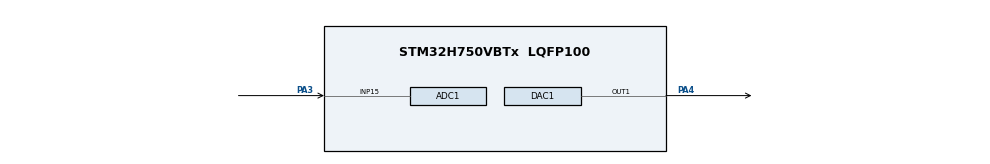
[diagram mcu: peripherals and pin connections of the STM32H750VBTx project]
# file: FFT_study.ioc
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ADC1.Channel-0\#ChannelRegularConversion=ADC_CHANNEL_15
ADC1.ClockPrescaler=ADC_CLOCK_ASYNC_DIV2
ADC1.ContinuousConvMode=DISABLE
ADC1.ConversionDataManagement=ADC_CONVERSIONDATA_DMA_CIRCULAR
ADC1.ExternalTrigConv=ADC_EXTERNALTRIG_T2_TRGO
ADC1.NbrOfConversionFlag=1
ADC1.OffsetNumber-0\#ChannelRegularConversion=ADC_OFFSET_NONE
ADC1.OffsetSignedSaturation-0\#ChannelRegularConversion=DISABLE
ADC1.Rank-0\#ChannelRegularConversion=1
ADC1.Resolution=ADC_RESOLUTION_12B
ADC1.SamplingTime-0\#ChannelRegularConversion=ADC_SAMPLETIME_64CYCLES_5
ADC1.master=1
CORTEX_M7.default_mode_Activation=1
DAC1.DAC_Channel-DAC_OUT1_ExtAndInt=DAC_CHANNEL_1
DAC1.DAC_Trigger-DAC_OUT1_ExtAndInt=DAC_TRIGGER_T2_TRGO
Dma.ADC1.1.Direction=DMA_PERIPH_TO_MEMORY
Dma.ADC1.1.EventEnable=DISABLE
Dma.ADC1.1.FIFOMode=DMA_FIFOMODE_DISABLE
Dma.ADC1.1.Instance=DMA2_Stream0
Dma.ADC1.1.MemDataAlignment=DMA_MDATAALIGN_HALFWORD
Dma.ADC1.1.MemInc=DMA_MINC_ENABLE
Dma.ADC1.1.Mode=DMA_CIRCULAR
Dma.ADC1.1.PeriphDataAlignment=DMA_PDATAALIGN_HALFWORD
Dma.ADC1.1.PeriphInc=DMA_PINC_DISABLE
Dma.ADC1.1.Polarity=HAL_DMAMUX_REQ_GEN_RISING
Dma.ADC1.1.Priority=DMA_PRIORITY_LOW
Dma.ADC1.1.RequestNumber=1
Dma.ADC1.1.SignalID=NONE
Dma.ADC1.1.SyncEnable=DISABLE
Dma.ADC1.1.SyncPolarity=HAL_DMAMUX_SYNC_NO_EVENT
Dma.ADC1.1.SyncRequestNumber=1
Dma.ADC1.1.SyncSignalID=NONE
Dma.DAC1_CH1.0.Direction=DMA_MEMORY_TO_PERIPH
Dma.DAC1_CH1.0.EventEnable=DISABLE
Dma.DAC1_CH1.0.FIFOMode=DMA_FIFOMODE_DISABLE
Dma.DAC1_CH1.0.Instance=DMA1_Stream0
Dma.DAC1_CH1.0.MemDataAlignment=DMA_MDATAALIGN_HALFWORD
Dma.DAC1_CH1.0.MemInc=DMA_MINC_ENABLE
Dma.DAC1_CH1.0.Mode=DMA_CIRCULAR
Dma.DAC1_CH1.0.PeriphDataAlignment=DMA_PDATAALIGN_HALFWORD
Dma.DAC1_CH1.0.PeriphInc=DMA_PINC_DISABLE
Dma.DAC1_CH1.0.Polarity=HAL_DMAMUX_REQ_GEN_RISING
Dma.DAC1_CH1.0.Priority=DMA_PRIORITY_LOW
Dma.DAC1_CH1.0.RequestNumber=1
Dma.DAC1_CH1.0.SignalID=NONE
Dma.DAC1_CH1.0.SyncEnable=DISABLE
Dma.DAC1_CH1.0.SyncPolarity=HAL_DMAMUX_SYNC_NO_EVENT
Dma.DAC1_CH1.0.SyncRequestNumber=1
Dma.DAC1_CH1.0.SyncSignalID=NONE
Dma.Request0=DAC1_CH1
Dma.Request1=ADC1
Mcu.Family=STM32H7
Mcu.Name=STM32H750VBTx
Mcu.Package=LQFP100
NVIC.DMA1_Stream0_IRQn=true\:0\:0\:false\:false\:true\:false\:true\:true
NVIC.DMA2_Stream0_IRQn=true\:0\:0\:false\:false\:true\:false\:true\:true
NVIC.PriorityGroup=NVIC_PRIORITYGROUP_4
PA3.Signal=ADCx_INP15
PA4.Signal=COMP_DAC11_group
ProjectManager.HeapSize=0x200
ProjectManager.StackSize=0x400
ProjectManager.TargetToolchain=MDK-ARM V5.32
RCC.ADCFreq_Value=80000000
RCC.APB1Freq_Value=120000000
RCC.APB2Freq_Value=120000000
RCC.APB3Freq_Value=120000000
RCC.APB4Freq_Value=120000000
RCC.CortexFreq_Value=480000000
RCC.D1PPRE=RCC_APB3_DIV2
RCC.D2PPRE1=RCC_APB1_DIV2
RCC.D2PPRE2=RCC_APB2_DIV2
RCC.D3PPRE=RCC_APB4_DIV2
RCC.DIVM1=4
RCC.DIVM2=4
RCC.DIVN1=60
RCC.DIVN2=10
RCC.HCLKFreq_Value=240000000
RCC.HPRE=RCC_HCLK_DIV2
RCC.PLL2FRACN=0
RCC.PLL2_VCI_Range=RCC_PLL2VCIRANGE_3
RCC.PLL3FRACN=0
RCC.PLLFRACN=0
RCC.SYSCLKFreq_VALUE=480000000
RCC.SYSCLKSource=RCC_SYSCLKSOURCE_PLLCLK
RCC.USBFreq_Value=480000000
SH.ADCx_INP15.0=ADC1_INP15,IN15-Single-Ended
SH.COMP_DAC11_group.0=DAC1_OUT1,DAC_OUT1_ExtAndInt
TIM2.AutoReloadPreload=TIM_AUTORELOAD_PRELOAD_ENABLE
TIM2.CounterMode=TIM_COUNTERMODE_UP
TIM2.Period=1874
TIM2.TIM_MasterOutputTrigger=TIM_TRGO_UPDATE
TIM3.Period=1874
TIM3.TIM_MasterOutputTrigger=TIM_TRGO_UPDATE
VP_MEMORYMAP_VS_MEMORYMAP.Mode=CurAppReg
VP_TIM2_VS_ClockSourceINT.Mode=Internal
VP_TIM3_VS_ClockSourceINT.Mode=Internal
board=custom

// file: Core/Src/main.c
/* USER CODE BEGIN Header */
/**
  ******************************************************************************
  * @file           : main.c
  * @brief          : Main program body
  ******************************************************************************
  * @attention
  *
  * Copyright (c) 2026 STMicroelectronics.
  * All rights reserved.
  *
  * This software is licensed under terms that can be found in the LICENSE file
  * in the root directory of this software component.
  * If no LICENSE file comes with this software, it is provided AS-IS.
  *
  ******************************************************************************
  */
/* USER CODE END Header */
#include "main.h"

/* USER CODE BEGIN Includes */
#include "arm_math.h"
/* USER CODE END Includes */

/* USER CODE BEGIN PD */
#define DMA_BUF __attribute__((section(".RAM_D1"), aligned(32)))

/* USER CODE END PD */

ADC_HandleTypeDef hadc1;
DMA_HandleTypeDef hdma_adc1;

DAC_HandleTypeDef hdac1;
DMA_HandleTypeDef hdma_dac1_ch1;

TIM_HandleTypeDef htim2;
TIM_HandleTypeDef htim3;

void SystemClock_Config(void);
static void MPU_Config(void);
static void MX_GPIO_Init(void);
static void MX_DMA_Init(void);
static void MX_DAC1_Init(void);
static void MX_ADC1_Init(void);
static void MX_TIM2_Init(void);
static void MX_TIM3_Init(void);

/* USER CODE BEGIN 0 */
uint16_t task=2;

DMA_BUF uint16_t dac_buf[128];

float32_t fft_input[256];
float32_t fft_out[256];
DMA_BUF uint16_t wave_sine[128]={0};
DMA_BUF uint16_t adc_buf[128];
volatile uint16_t adc_max=0, adc_min=4095;
volatile uint32_t adc_mean=0, adc_cross=0;
volatile uint8_t done=0;
/* USER CODE END 0 */

int main(void)
{

  /* MPU Configuration--------------------------------------------------------*/
  MPU_Config();

  /* MCU Configuration--------------------------------------------------------*/

  /* Reset of all peripherals, Initializes the Flash interface and the Systick. */
  HAL_Init();

  /* Configure the system clock */
  SystemClock_Config();

  /* Initialize all configured peripherals */
  MX_GPIO_Init();
  MX_DMA_Init();
  MX_DAC1_Init();
  MX_ADC1_Init();
  MX_TIM2_Init();
  MX_TIM3_Init();
  /* USER CODE BEGIN 2 */

  //开DAC，填波形表
  HAL_DAC_Start(&hdac1, DAC_CHANNEL_1);
  for (uint16_t i=0 ; i<128 ; i++ ){
	  wave_sine[i]=2048+2047*sinf(2*PI*i/128);
	}

	//把填好的表传
  SCB_CleanDCache_by_Addr((uint32_t*)wave_sine, sizeof(wave_sine));
	if (task == 1) {
    HAL_DAC_Start_DMA(&hdac1, DAC_CHANNEL_1, (uint32_t*)wave_sine, 128, DAC_ALIGN_12B_R);
} else {
    HAL_DAC_Start_DMA(&hdac1, DAC_CHANNEL_1, (uint32_t*)dac_buf, 128, DAC_ALIGN_12B_R);
}

	HAL_ADC_Start_DMA(&hadc1, (uint32_t*)adc_buf, 128);

  HAL_TIM_Base_Start(&htim2);
  HAL_TIM_Base_Start(&htim3);

	arm_rfft_fast_instance_f32 ffthandle;
  arm_rfft_fast_init_f32(&ffthandle, 256);

	float max_mag = 0;
	uint16_t max_bin = 0;
  /* USER CODE END 2 */

  /* Infinite loop */
  while (1)
  {

    /* USER CODE BEGIN 3 */

	if(done==1){
		done=0;
		if (task == 1) {        // 减均值 → 填 fft_input → FFT → 找峰
					for(uint16_t i=0;i<256;i++){
			fft_input[i] = (float)adc_buf[i] - (float)adc_mean;
	}
		arm_rfft_fast_f32(&ffthandle, fft_input, fft_out, 0);

		max_mag=0;
		for (uint16_t k = 1; k < 128; k++) {      // 跳过 bin0（直流）
			float re = fft_out[2*k];
			float im = fft_out[2*k+1];
			float mag = re*re + im*im;            // 幅度平方，省 sqrt，不影响找最大
			if (mag > max_mag) {
        max_mag = mag;
        max_bin = k;
    }
}
    } else {
			for(uint16_t i=0;i<128;i++){
			dac_buf[i]=adc_buf[i];
			}
       SCB_CleanDCache_by_Addr((uint32_t*)dac_buf, sizeof(dac_buf)); // 复制 adc_buf → dac_buf（不减均值！）
      }
		}
	}
  /* USER CODE END 3 */
}

void SystemClock_Config(void)
{
  RCC_OscInitTypeDef RCC_OscInitStruct = {0};
  RCC_ClkInitTypeDef RCC_ClkInitStruct = {0};

  /** Supply configuration update enable
  */
  HAL_PWREx_ConfigSupply(PWR_LDO_SUPPLY);

  /** Configure the main internal regulator output voltage
  */
  __HAL_PWR_VOLTAGESCALING_CONFIG(PWR_REGULATOR_VOLTAGE_SCALE0);

  while(!__HAL_PWR_GET_FLAG(PWR_FLAG_VOSRDY)) {}

  /** Initializes the RCC Oscillators according to the specified parameters
  * in the RCC_OscInitTypeDef structure.
  */
  RCC_OscInitStruct.OscillatorType = RCC_OSCILLATORTYPE_HSI;
  RCC_OscInitStruct.HSIState = RCC_HSI_DIV1;
  RCC_OscInitStruct.HSICalibrationValue = RCC_HSICALIBRATION_DEFAULT;
  RCC_OscInitStruct.PLL.PLLState = RCC_PLL_ON;
  RCC_OscInitStruct.PLL.PLLSource = RCC_PLLSOURCE_HSI;
  RCC_OscInitStruct.PLL.PLLM = 4;
  RCC_OscInitStruct.PLL.PLLN = 60;
  RCC_OscInitStruct.PLL.PLLP = 2;
  RCC_OscInitStruct.PLL.PLLQ = 2;
  RCC_OscInitStruct.PLL.PLLR = 2;
  RCC_OscInitStruct.PLL.PLLRGE = RCC_PLL1VCIRANGE_3;
  RCC_OscInitStruct.PLL.PLLVCOSEL = RCC_PLL1VCOWIDE;
  RCC_OscInitStruct.PLL.PLLFRACN = 0;
  if (HAL_RCC_OscConfig(&RCC_OscInitStruct) != HAL_OK)
  {
    Error_Handler();
  }

  /** Initializes the CPU, AHB and APB buses clocks
  */
  RCC_ClkInitStruct.ClockType = RCC_CLOCKTYPE_HCLK|RCC_CLOCKTYPE_SYSCLK
                              |RCC_CLOCKTYPE_PCLK1|RCC_CLOCKTYPE_PCLK2
                              |RCC_CLOCKTYPE_D3PCLK1|RCC_CLOCKTYPE_D1PCLK1;
  RCC_ClkInitStruct.SYSCLKSource = RCC_SYSCLKSOURCE_PLLCLK;
  RCC_ClkInitStruct.SYSCLKDivider = RCC_SYSCLK_DIV1;
  RCC_ClkInitStruct.AHBCLKDivider = RCC_HCLK_DIV2;
  RCC_ClkInitStruct.APB3CLKDivider = RCC_APB3_DIV2;
  RCC_ClkInitStruct.APB1CLKDivider = RCC_APB1_DIV2;
  RCC_ClkInitStruct.APB2CLKDivider = RCC_APB2_DIV2;
  RCC_ClkInitStruct.APB4CLKDivider = RCC_APB4_DIV2;

  if (HAL_RCC_ClockConfig(&RCC_ClkInitStruct, FLASH_LATENCY_4) != HAL_OK)
  {
    Error_Handler();
  }
}

static void MX_ADC1_Init(void)
{

  ADC_MultiModeTypeDef multimode = {0};
  ADC_ChannelConfTypeDef sConfig = {0};

  /** Common config
  */
  hadc1.Instance = ADC1;
  hadc1.Init.ClockPrescaler = ADC_CLOCK_ASYNC_DIV2;
  hadc1.Init.Resolution = ADC_RESOLUTION_12B;
  hadc1.Init.ScanConvMode = ADC_SCAN_DISABLE;
  hadc1.Init.EOCSelection = ADC_EOC_SINGLE_CONV;
  hadc1.Init.LowPowerAutoWait = DISABLE;
  hadc1.Init.ContinuousConvMode = DISABLE;
  hadc1.Init.NbrOfConversion = 1;
  hadc1.Init.DiscontinuousConvMode = DISABLE;
  hadc1.Init.ExternalTrigConv = ADC_EXTERNALTRIG_T2_TRGO;
  hadc1.Init.ExternalTrigConvEdge = ADC_EXTERNALTRIGCONVEDGE_RISING;
  hadc1.Init.ConversionDataManagement = ADC_CONVERSIONDATA_DMA_CIRCULAR;
  hadc1.Init.Overrun = ADC_OVR_DATA_PRESERVED;
  hadc1.Init.LeftBitShift = ADC_LEFTBITSHIFT_NONE;
  hadc1.Init.OversamplingMode = DISABLE;
  hadc1.Init.Oversampling.Ratio = 1;
  if (HAL_ADC_Init(&hadc1) != HAL_OK)
  {
    Error_Handler();
  }

  /** Configure the ADC multi-mode
  */
  multimode.Mode = ADC_MODE_INDEPENDENT;
  if (HAL_ADCEx_MultiModeConfigChannel(&hadc1, &multimode) != HAL_OK)
  {
    Error_Handler();
  }

  /** Configure Regular Channel
  */
  sConfig.Channel = ADC_CHANNEL_15;
  sConfig.Rank = ADC_REGULAR_RANK_1;
  sConfig.SamplingTime = ADC_SAMPLETIME_64CYCLES_5;
  sConfig.SingleDiff = ADC_SINGLE_ENDED;
  sConfig.OffsetNumber = ADC_OFFSET_NONE;
  sConfig.Offset = 0;
  sConfig.OffsetSignedSaturation = DISABLE;
  if (HAL_ADC_ConfigChannel(&hadc1, &sConfig) != HAL_OK)
  {
    Error_Handler();
  }

}

static void MX_DAC1_Init(void)
{

  DAC_ChannelConfTypeDef sConfig = {0};

  /** DAC Initialization
  */
  hdac1.Instance = DAC1;
  if (HAL_DAC_Init(&hdac1) != HAL_OK)
  {
    Error_Handler();
  }

  /** DAC channel OUT1 config
  */
  sConfig.DAC_SampleAndHold = DAC_SAMPLEANDHOLD_DISABLE;
  sConfig.DAC_Trigger = DAC_TRIGGER_T2_TRGO;
  sConfig.DAC_OutputBuffer = DAC_OUTPUTBUFFER_ENABLE;
  sConfig.DAC_ConnectOnChipPeripheral = DAC_CHIPCONNECT_ENABLE;
  sConfig.DAC_UserTrimming = DAC_TRIMMING_FACTORY;
  if (HAL_DAC_ConfigChannel(&hdac1, &sConfig, DAC_CHANNEL_1) != HAL_OK)
  {
    Error_Handler();
  }

}

static void MX_TIM2_Init(void)
{

  TIM_ClockConfigTypeDef sClockSourceConfig = {0};
  TIM_MasterConfigTypeDef sMasterConfig = {0};

  htim2.Instance = TIM2;
  htim2.Init.Prescaler = 0;
  htim2.Init.CounterMode = TIM_COUNTERMODE_UP;
  htim2.Init.Period = 185;
  htim2.Init.ClockDivision = TIM_CLOCKDIVISION_DIV1;
  htim2.Init.AutoReloadPreload = TIM_AUTORELOAD_PRELOAD_ENABLE;
  if (HAL_TIM_Base_Init(&htim2) != HAL_OK)
  {
    Error_Handler();
  }
  sClockSourceConfig.ClockSource = TIM_CLOCKSOURCE_INTERNAL;
  if (HAL_TIM_ConfigClockSource(&htim2, &sClockSourceConfig) != HAL_OK)
  {
    Error_Handler();
  }
  sMasterConfig.MasterOutputTrigger = TIM_TRGO_UPDATE;
  sMasterConfig.MasterSlaveMode = TIM_MASTERSLAVEMODE_DISABLE;
  if (HAL_TIMEx_MasterConfigSynchronization(&htim2, &sMasterConfig) != HAL_OK)
  {
    Error_Handler();
  }

}

static void MX_TIM3_Init(void)
{

  TIM_ClockConfigTypeDef sClockSourceConfig = {0};
  TIM_MasterConfigTypeDef sMasterConfig = {0};

  htim3.Instance = TIM3;
  htim3.Init.Prescaler = 0;
  htim3.Init.CounterMode = TIM_COUNTERMODE_UP;
  htim3.Init.Period = 0;
  htim3.Init.ClockDivision = TIM_CLOCKDIVISION_DIV1;
  htim3.Init.AutoReloadPreload = TIM_AUTORELOAD_PRELOAD_DISABLE;
  if (HAL_TIM_Base_Init(&htim3) != HAL_OK)
  {
    Error_Handler();
  }
  sClockSourceConfig.ClockSource = TIM_CLOCKSOURCE_INTERNAL;
  if (HAL_TIM_ConfigClockSource(&htim3, &sClockSourceConfig) != HAL_OK)
  {
    Error_Handler();
  }
  sMasterConfig.MasterOutputTrigger = TIM_TRGO_UPDATE;
  sMasterConfig.MasterSlaveMode = TIM_MASTERSLAVEMODE_DISABLE;
  if (HAL_TIMEx_MasterConfigSynchronization(&htim3, &sMasterConfig) != HAL_OK)
  {
    Error_Handler();
  }

}

static void MX_DMA_Init(void)
{

  /* DMA controller clock enable */
  __HAL_RCC_DMA1_CLK_ENABLE();
  __HAL_RCC_DMA2_CLK_ENABLE();

  /* DMA interrupt init */
  /* DMA1_Stream0_IRQn interrupt configuration */
  HAL_NVIC_SetPriority(DMA1_Stream0_IRQn, 0, 0);
  HAL_NVIC_EnableIRQ(DMA1_Stream0_IRQn);
  /* DMA2_Stream0_IRQn interrupt configuration */
  HAL_NVIC_SetPriority(DMA2_Stream0_IRQn, 0, 0);
  HAL_NVIC_EnableIRQ(DMA2_Stream0_IRQn);

}

static void MX_GPIO_Init(void)
{

  /* GPIO Ports Clock Enable */
  __HAL_RCC_GPIOA_CLK_ENABLE();

}

/* USER CODE BEGIN 4 */
void HAL_ADC_ConvCpltCallback(ADC_HandleTypeDef *hadc) //不用示波器验证，HAL 库在中断里自动调用这个函数
{
if (hadc->Instance != ADC1) return;
SCB_InvalidateDCache_by_Addr((uint32_t*)adc_buf, sizeof(adc_buf));

adc_max = 0;
adc_min = 4095;
adc_mean = 0;
adc_cross = 0;

    for (uint16_t i = 0; i < 1; i++) {
        if (adc_buf[i] > adc_max) adc_max = adc_buf[i];     // 更大就更新
        if (adc_buf[i] < adc_min) adc_min = adc_buf[i];     // 更小就更新
        adc_mean += adc_buf[i];
        if (i > 0 && adc_buf[i-1] < 2048 && adc_buf[i] >= 2048) adc_cross++;
    }

    adc_mean /= 256;
    done = 1;

}

/* USER CODE END 4 */

 /* MPU Configuration */

void MPU_Config(void)
{
  MPU_Region_InitTypeDef MPU_InitStruct = {0};

  /* Disables the MPU */
  HAL_MPU_Disable();

  /** Initializes and configures the Region and the memory to be protected
  */
  MPU_InitStruct.Enable = MPU_REGION_ENABLE;
  MPU_InitStruct.Number = MPU_REGION_NUMBER0;
  MPU_InitStruct.BaseAddress = 0x0;
  MPU_InitStruct.Size = MPU_REGION_SIZE_4GB;
  MPU_InitStruct.SubRegionDisable = 0x87;
  MPU_InitStruct.TypeExtField = MPU_TEX_LEVEL0;
  MPU_InitStruct.AccessPermission = MPU_REGION_NO_ACCESS;
  MPU_InitStruct.DisableExec = MPU_INSTRUCTION_ACCESS_DISABLE;
  MPU_InitStruct.IsShareable = MPU_ACCESS_SHAREABLE;
  MPU_InitStruct.IsCacheable = MPU_ACCESS_NOT_CACHEABLE;
  MPU_InitStruct.IsBufferable = MPU_ACCESS_NOT_BUFFERABLE;

  HAL_MPU_ConfigRegion(&MPU_InitStruct);
  /* Enables the MPU */
  HAL_MPU_Enable(MPU_PRIVILEGED_DEFAULT);

}

void Error_Handler(void)
{
  __disable_irq();
  while (1)
  {
  }
}
